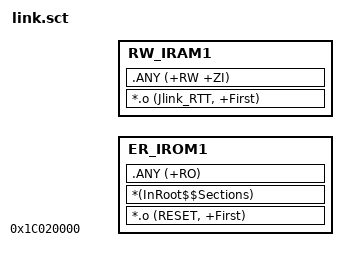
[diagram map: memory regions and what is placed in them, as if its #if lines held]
#! armclang -E --target=arm-arm-none-eabi -mcpu=cortex-m33 -xc -I $SDK_ROOT/drivers/cmsis/sf32lb58x -I $BSP_ROOT
#include "rtconfig.h"
#include "mem_map.h"

; *************************************************************
; *** Scatter-Loading Description File generated by uVision ***
; *************************************************************

LR_IROM1 0x1C020000 BOOTLOADER_CODE_SIZE *2 {    ; load region size_region, 
  ER_IROM1 0x1C020000 BOOTLOADER_CODE_SIZE *2 {  ; load address = execution address
   *.o (RESET, +First)
   *(InRoot$$Sections)
   .ANY (+RO)
  }
  ; 0x10000 to 0x80000 reserved to simulate flash.
  RW_IRAM1 BOOTLOADER_RAM_DATA_START_ADDR BOOTLOADER_RAM_DATA_SIZE  {  ; RW data
#ifdef BSP_USING_JLINK_RTT    
   *.o (Jlink_RTT, +First)
#endif   
   .ANY (+RW +ZI)
  }
}
